VERSION ""

NS_ :

BS_:

BU_: GWS2 CAS EGS

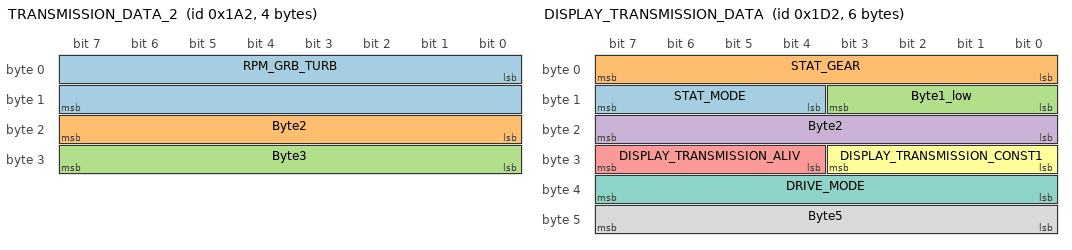
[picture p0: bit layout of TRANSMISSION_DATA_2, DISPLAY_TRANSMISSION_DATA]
BO_ 418 TRANSMISSION_DATA_2: 4 EGS
 SG_ RPM_GRB_TURB : 0|16@1+ (0.125,6) [0|8191.75] "1/min" Vector__XXX
 SG_ Byte2 : 16|8@1+ (1,0) [0|254] "" Vector__XXX
 SG_ Byte3 : 24|8@1+ (1,0) [0|254] "" Vector__XXX

BO_ 466 DISPLAY_TRANSMISSION_DATA: 6 EGS
 SG_ STAT_MODE : 12|4@1+ (1,0) [0|0] "" Vector__XXX
 SG_ STAT_GEAR : 0|8@1+ (1,0) [0|0] "" Vector__XXX
 SG_ Byte1_low : 8|4@1+ (1,0) [0|0] "" Vector__XXX
 SG_ Byte2 : 16|8@1+ (1,0) [0|0] "" Vector__XXX
 SG_ DISPLAY_TRANSMISSION_ALIV : 28|4@1+ (1,0) [0|14] "" Vector__XXX
 SG_ DISPLAY_TRANSMISSION_CONST1 : 24|4@1+ (1,0) [0|14] "" Vector__XXX
 SG_ DRIVE_MODE : 32|8@1+ (1,0) [0|0] "" Vector__XXX
 SG_ Byte5 : 40|8@1+ (1,0) [0|0] "" Vector__XXX

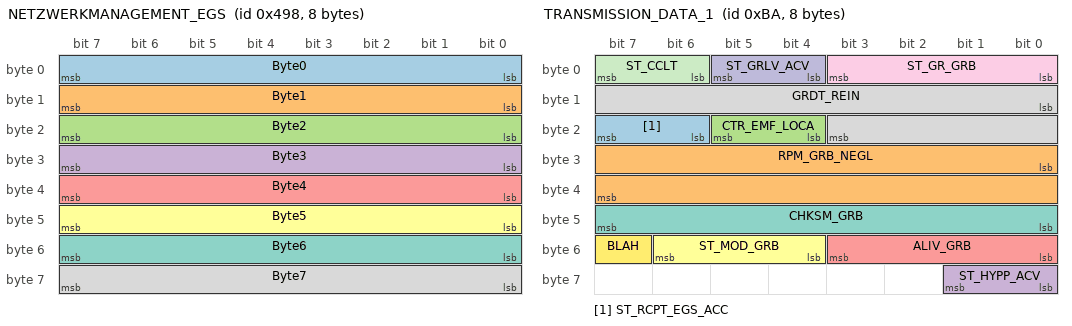
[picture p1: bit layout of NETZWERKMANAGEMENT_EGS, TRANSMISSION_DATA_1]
BO_ 1176 NETZWERKMANAGEMENT_EGS: 8 EGS
 SG_ Byte0 : 0|8@1+ (1,0) [0|254] "" Vector__XXX
 SG_ Byte1 : 8|8@1+ (1,0) [0|0] "" Vector__XXX
 SG_ Byte2 : 16|8@1+ (1,0) [0|0] "" Vector__XXX
 SG_ Byte3 : 24|8@1+ (1,0) [0|0] "" Vector__XXX
 SG_ Byte4 : 32|8@1+ (1,0) [0|0] "" Vector__XXX
 SG_ Byte5 : 40|8@1+ (1,0) [0|0] "" Vector__XXX
 SG_ Byte6 : 48|8@1+ (1,0) [0|0] "" Vector__XXX
 SG_ Byte7 : 56|8@1+ (1,0) [0|0] "" Vector__XXX

BO_ 186 TRANSMISSION_DATA_1: 8 EGS
 SG_ ST_RCPT_EGS_ACC : 22|2@1+ (1,0) [0|0] "" Vector__XXX
 SG_ RPM_GRB_NEGL : 24|16@1+ (0.125,0) [0|0] "1/min" Vector__XXX
 SG_ CTR_EMF_LOCA : 20|2@1+ (1,0) [0|0] "" Vector__XXX
 SG_ ST_HYPP_ACV : 56|2@1+ (1,0) [0|0] "" Vector__XXX
 SG_ ALIV_GRB : 48|4@1+ (1,0) [0|0] "" Vector__XXX
 SG_ ST_MOD_GRB : 52|3@1+ (1,0) [0|0] "" Vector__XXX
 SG_ CHKSM_GRB : 40|8@1+ (1,0) [0|0] "" Vector__XXX
 SG_ GRDT_REIN : 8|12@1+ (0.125,0) [0|0] "1/m" Vector__XXX
 SG_ ST_GR_GRB : 0|4@1+ (1,0) [0|0] "" Vector__XXX
 SG_ ST_GRLV_ACV : 4|2@1+ (1,0) [0|0] "" Vector__XXX
 SG_ ST_CCLT : 6|2@1+ (1,0) [0|0] "" Vector__XXX
 SG_ BLAH : 55|1@1+ (1,0) [0|0] "" Vector__XXX

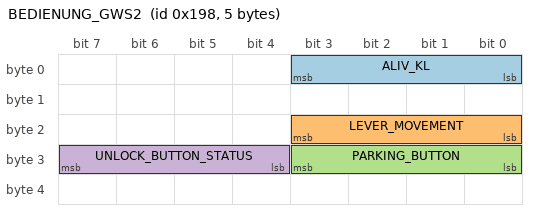
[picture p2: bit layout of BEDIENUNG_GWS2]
BO_ 408 BEDIENUNG_GWS2: 5 GWS2
 SG_ ALIV_KL : 0|4@1+ (1,0) [0|14] "" Vector__XXX
 SG_ LEVER_MOVEMENT : 16|4@1+ (1,0) [0|14] "" Vector__XXX
 SG_ PARKING_BUTTON : 24|4@1+ (1,0) [0|14] "" Vector__XXX
 SG_ UNLOCK_BUTTON_STATUS : 28|4@1+ (1,0) [0|14] "" Vector__XXX

CM_ SG_ 466 Byte2 "0x8B or 0x8D, constant values";
VAL_ 466 STAT_MODE 10 "M6" 9 "M5" 8 "M4" 7 "M3" 6 "M2" 5 "M1" 0 "Automatic" ;
VAL_ 466 STAT_GEAR 225 "P" 210 "R" 180 "N" 120 "D" ;
VAL_ 466 DRIVE_MODE 242 "Drive mode, ena manual" 241 "Drive mode, sport (?)" 240 "Drive mode, automatic" 207 "Non-drive mode (Pn or N)" ;
VAL_ 408 UNLOCK_BUTTON_STATUS 12 "Unpressed" 9 "Pressed" ;
VAL_ 408 PARKING_BUTTON 5 "Pressed_5" 4 "Pressed_4" 3 "Pressed_3" 2 "Pressed_2" 1 "Pressed_1" 0 "Unpressed";
VAL_ 408 LEVER_MOVEMENT 15 "Untoched" 14 "Push up" 13 "Over-push up" 12 "Pull down" 11 "Over-pull down";
